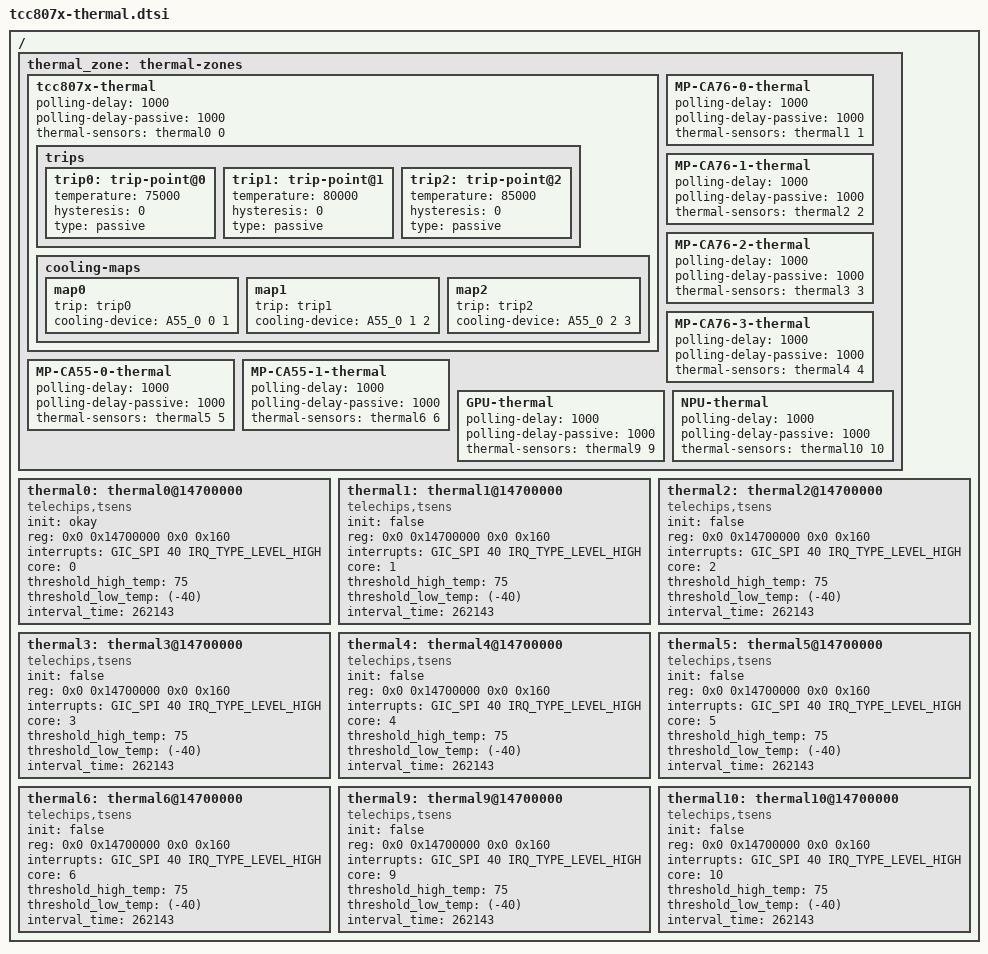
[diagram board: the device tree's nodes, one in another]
// SPDX-License-Identifier: (GPL-2.0-or-later OR MIT)
/*
 * Copyright (C) 2023 Telechips Inc.
 */

#include <dt-bindings/interrupt-controller/arm-gic.h>
#include <dt-bindings/thermal/thermal.h>

/ {
	thermal_zone: thermal-zones {
		tcc807x-thermal {
			polling-delay = <1000>;
			polling-delay-passive = <1000>;
			thermal-sensors = <&thermal0 0>;

			trips {
				trip0: trip-point@0 {
					temperature = <75000>;
					hysteresis = <0>;
					type = "passive";
				};
				trip1: trip-point@1 {
					temperature = <80000>;
					hysteresis = <0>;
					type = "passive";
				};
				trip2: trip-point@2 {
					temperature = <85000>;
					hysteresis = <0>;
					type = "passive";
				};
			};

			cooling-maps {
				map0 {
					trip = <&trip0>;
					cooling-device =
						<&A55_0 0 1>;
				};
				map1 {
					trip = <&trip1>;
					cooling-device =
						<&A55_0 1 2>;
				};
				map2 {
					trip = <&trip2>;
					cooling-device =
						<&A55_0 2 3>;
				};
			};
		};

		MP-CA76-0-thermal {
			polling-delay = <1000>;
			polling-delay-passive = <1000>;
			thermal-sensors = <&thermal1 1>;
		};

		MP-CA76-1-thermal {
			polling-delay = <1000>;
			polling-delay-passive = <1000>;
			thermal-sensors = <&thermal2 2>;
		};

		MP-CA76-2-thermal {
			polling-delay = <1000>;
			polling-delay-passive = <1000>;
			thermal-sensors = <&thermal3 3>;
		};
		MP-CA76-3-thermal {
			polling-delay = <1000>;
			polling-delay-passive = <1000>;
			thermal-sensors = <&thermal4 4>;
		};
		MP-CA55-0-thermal {
			polling-delay = <1000>;
			polling-delay-passive = <1000>;
			thermal-sensors = <&thermal5 5>;
		};
		MP-CA55-1-thermal {
			polling-delay = <1000>;
			polling-delay-passive = <1000>;
			thermal-sensors = <&thermal6 6>;
		};
		GPU-thermal {
			polling-delay = <1000>;
			polling-delay-passive = <1000>;
			thermal-sensors = <&thermal9 9>;
		};
		NPU-thermal {
			polling-delay = <1000>;
			polling-delay-passive = <1000>;
			thermal-sensors = <&thermal10 10>;
		};
	};

	thermal0: thermal0@14700000 {
		compatible = "telechips,tsens";

		init = "okay";
		reg = <0x0 0x14700000 0x0 0x160>; //0:Enable register
		status = "okay";

		interrupts = <GIC_SPI 40 IRQ_TYPE_LEVEL_HIGH>;
		core = <0>;

		threshold_high_temp = <75>;
		threshold_low_temp = <(-40)>;
		interval_time = <262143>;
		#thermal-sensor-cells = <1>;
	};

	thermal1: thermal1@14700000 {
		compatible = "telechips,tsens";

		init = "false";
		reg = <0x0 0x14700000 0x0 0x160>; //0:Enable register
		status = "okay";

		interrupts = <GIC_SPI 40 IRQ_TYPE_LEVEL_HIGH>;
		core = <1>;

		threshold_high_temp = <75>;
		threshold_low_temp = <(-40)>;
		interval_time = <262143>;
		#thermal-sensor-cells = <1>;
	};

	thermal2: thermal2@14700000 {
		compatible = "telechips,tsens";

		init = "false";
		reg = <0x0 0x14700000 0x0 0x160>; //0:Enable register
		status = "okay";

		interrupts = <GIC_SPI 40 IRQ_TYPE_LEVEL_HIGH>;
		core = <2>;

		threshold_high_temp = <75>;
		threshold_low_temp = <(-40)>;
		interval_time = <262143>;
		#thermal-sensor-cells = <1>;
	};

	thermal3: thermal3@14700000 {
		compatible = "telechips,tsens";

		init = "false";
		reg = <0x0 0x14700000 0x0 0x160>; //0:Enable register
		status = "okay";

		interrupts = <GIC_SPI 40 IRQ_TYPE_LEVEL_HIGH>;
		core = <3>;

		threshold_high_temp = <75>;
		threshold_low_temp = <(-40)>;
		interval_time = <262143>;
		#thermal-sensor-cells = <1>;
	};

	thermal4: thermal4@14700000 {
		compatible = "telechips,tsens";

		init = "false";
		reg = <0x0 0x14700000 0x0 0x160>; //0:Enable register
		status = "okay";

		interrupts = <GIC_SPI 40 IRQ_TYPE_LEVEL_HIGH>;
		core = <4>;

		threshold_high_temp = <75>;
		threshold_low_temp = <(-40)>;
		interval_time = <262143>;
		#thermal-sensor-cells = <1>;
	};

	thermal5: thermal5@14700000 {
		compatible = "telechips,tsens";

		init = "false";
		reg = <0x0 0x14700000 0x0 0x160>; //0:Enable register
		status = "okay";

		interrupts = <GIC_SPI 40 IRQ_TYPE_LEVEL_HIGH>;
		core = <5>;

		threshold_high_temp = <75>;
		threshold_low_temp = <(-40)>;
		interval_time = <262143>;
		#thermal-sensor-cells = <1>;
	};


	thermal6: thermal6@14700000 {
		compatible = "telechips,tsens";

		init = "false";
		reg = <0x0 0x14700000 0x0 0x160>; //0:Enable register
		status = "okay";

		interrupts = <GIC_SPI 40 IRQ_TYPE_LEVEL_HIGH>;
		core = <6>;

		threshold_high_temp = <75>;
		threshold_low_temp = <(-40)>;
		interval_time = <262143>;
		#thermal-sensor-cells = <1>;
	};

	thermal9: thermal9@14700000 {
		compatible = "telechips,tsens";

		init = "false";
		reg = <0x0 0x14700000 0x0 0x160>; //0:Enable register
		status = "okay";

		interrupts = <GIC_SPI 40 IRQ_TYPE_LEVEL_HIGH>;
		core = <9>;

		threshold_high_temp = <75>;
		threshold_low_temp = <(-40)>;
		interval_time = <262143>;
		#thermal-sensor-cells = <1>;
	};

	thermal10: thermal10@14700000 {
		compatible = "telechips,tsens";

		init = "false";
		reg = <0x0 0x14700000 0x0 0x160>; //0:Enable register
		status = "okay";

		interrupts = <GIC_SPI 40 IRQ_TYPE_LEVEL_HIGH>;
		core = <10>;

		threshold_high_temp = <75>;
		threshold_low_temp = <(-40)>;
		interval_time = <262143>;
		#thermal-sensor-cells = <1>;
	};
};
